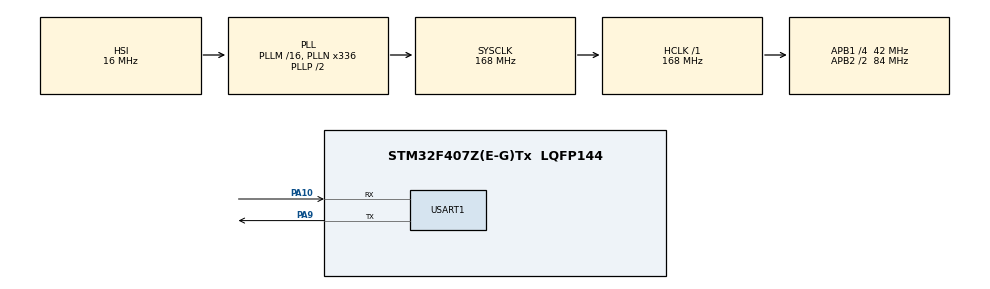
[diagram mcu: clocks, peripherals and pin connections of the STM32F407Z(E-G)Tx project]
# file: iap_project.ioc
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Mcu.Family=STM32F4
Mcu.Name=STM32F407Z(E-G)Tx
Mcu.Package=LQFP144
NVIC.PriorityGroup=NVIC_PRIORITYGROUP_4
NVIC.TIM6_DAC_IRQn=true\:0\:0\:false\:false\:true\:true\:true
NVIC.USART1_IRQn=true\:0\:0\:false\:false\:true\:true\:true
PA10.Mode=Asynchronous
PA10.Signal=USART1_RX
PA9.Mode=Asynchronous
PA9.Signal=USART1_TX
PC14-OSC32_IN.Mode=LSE-External-Oscillator
PC14-OSC32_IN.Signal=RCC_OSC32_IN
PC15-OSC32_OUT.Mode=LSE-External-Oscillator
PC15-OSC32_OUT.Signal=RCC_OSC32_OUT
PH0-OSC_IN.Mode=HSE-External-Oscillator
PH0-OSC_IN.Signal=RCC_OSC_IN
PH1-OSC_OUT.Mode=HSE-External-Oscillator
PH1-OSC_OUT.Signal=RCC_OSC_OUT
ProjectManager.HeapSize=0x200
ProjectManager.StackSize=0x400
ProjectManager.TargetToolchain=MDK-ARM V5
RCC.48MHZClocksFreq_Value=84000000
RCC.AHBFreq_Value=168000000
RCC.APB1CLKDivider=RCC_HCLK_DIV4
RCC.APB1Freq_Value=42000000
RCC.APB1TimFreq_Value=84000000
RCC.APB2CLKDivider=RCC_HCLK_DIV2
RCC.APB2Freq_Value=84000000
RCC.APB2TimFreq_Value=168000000
RCC.CortexFreq_Value=168000000
RCC.HCLKFreq_Value=168000000
RCC.HSE_VALUE=25000000
RCC.HSI_VALUE=16000000
RCC.PLLN=336
RCC.SYSCLKFreq_VALUE=168000000
RCC.SYSCLKSource=RCC_SYSCLKSOURCE_PLLCLK
RCC.VCOOutputFreq_Value=336000000
TIM6.AutoReloadPreload=TIM_AUTORELOAD_PRELOAD_ENABLE
TIM6.Period=999
TIM6.Prescaler=83
USART1.VirtualMode=VM_ASYNC
VP_TIM6_VS_ClockSourceINT.Mode=Enable_Timer
board=custom

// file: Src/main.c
/* USER CODE BEGIN Header */
/**
  ******************************************************************************
  * @file           : main.c
  * @brief          : Main program body
  ******************************************************************************
  * @attention
  *
  * <h2><center>&copy; Copyright (c) 2019 STMicroelectronics.
  * All rights reserved.</center></h2>
  *
  * This software component is licensed by ST under BSD 3-Clause license,
  * the "License"; You may not use this file except in compliance with the
  * License. You may obtain a copy of the License at:
  *                        opensource.org/licenses/BSD-3-Clause
  *
  ******************************************************************************
  */
/* USER CODE END Header */

#include "main.h"
#include "tim.h"
#include "usart.h"
#include "gpio.h"

/* USER CODE BEGIN Includes */
#include "stmflash.h"
#include "iap.h"
/* USER CODE END Includes */

void SystemClock_Config(void);

int main(void)
{

  /* MCU Configuration--------------------------------------------------------*/

  /* Reset of all peripherals, Initializes the Flash interface and the Systick. */
  HAL_Init();

  /* Configure the system clock */
  SystemClock_Config();

  /* Initialize all configured peripherals */
  MX_GPIO_Init();
  MX_USART1_UART_Init();
  MX_TIM6_Init();
  /* USER CODE BEGIN 2 */
	HAL_UART_Receive_IT(&huart1, (uint8_t*)&Res, 1);
	HAL_TIM_Base_Start_IT(&htim6);
	//STMFLASH_Write(ADDR_FLASH_SECTOR_9, &tmpText, 1);

  /* USER CODE END 2 */

  /* Infinite loop */
  /* USER CODE BEGIN WHILE */
  while (1)
  {
		HAL_Delay(100);
		if(rxFinishState == 1)
		{
			if(((*(volatile uint32_t*)(0X20001000+4))&0xFF000000)==0x08000000){//判断是否为0X08XXXXXX.
				IAP_Write_APPbin(FLASH_APP_ADDR, (uint8_t*)USART_RX_BUF, USART_RX_CNT);
				myPrintf("APP接收完成\r\n");
			}
			USART_RX_CNT = 0;
			rxFinishState = 0;
			if(((*(volatile uint32_t*)(0X20001000+4))&0xFF000000)==0x08000000){//判断是否为0X08XXXXXX.
				IAP_Load_APP(FLASH_APP_ADDR);
			}
		}
    /* USER CODE END WHILE */

  }
}

void SystemClock_Config(void)
{
  RCC_OscInitTypeDef RCC_OscInitStruct = {0};
  RCC_ClkInitTypeDef RCC_ClkInitStruct = {0};

  /** Configure the main internal regulator output voltage
  */
  __HAL_RCC_PWR_CLK_ENABLE();
  __HAL_PWR_VOLTAGESCALING_CONFIG(PWR_REGULATOR_VOLTAGE_SCALE1);
  /** Initializes the CPU, AHB and APB busses clocks
  */
  RCC_OscInitStruct.OscillatorType = RCC_OSCILLATORTYPE_HSI;
  RCC_OscInitStruct.HSIState = RCC_HSI_ON;
  RCC_OscInitStruct.HSICalibrationValue = RCC_HSICALIBRATION_DEFAULT;
  RCC_OscInitStruct.PLL.PLLState = RCC_PLL_ON;
  RCC_OscInitStruct.PLL.PLLSource = RCC_PLLSOURCE_HSI;
  RCC_OscInitStruct.PLL.PLLM = 16;
  RCC_OscInitStruct.PLL.PLLN = 336;
  RCC_OscInitStruct.PLL.PLLP = RCC_PLLP_DIV2;
  RCC_OscInitStruct.PLL.PLLQ = 4;
  if (HAL_RCC_OscConfig(&RCC_OscInitStruct) != HAL_OK)
  {
    Error_Handler();
  }
  /** Initializes the CPU, AHB and APB busses clocks
  */
  RCC_ClkInitStruct.ClockType = RCC_CLOCKTYPE_HCLK|RCC_CLOCKTYPE_SYSCLK
                              |RCC_CLOCKTYPE_PCLK1|RCC_CLOCKTYPE_PCLK2;
  RCC_ClkInitStruct.SYSCLKSource = RCC_SYSCLKSOURCE_PLLCLK;
  RCC_ClkInitStruct.AHBCLKDivider = RCC_SYSCLK_DIV1;
  RCC_ClkInitStruct.APB1CLKDivider = RCC_HCLK_DIV4;
  RCC_ClkInitStruct.APB2CLKDivider = RCC_HCLK_DIV2;

  if (HAL_RCC_ClockConfig(&RCC_ClkInitStruct, FLASH_LATENCY_5) != HAL_OK)
  {
    Error_Handler();
  }
}

void Error_Handler(void)
{
}

/************************ (C) COPYRIGHT STMicroelectronics *****END OF FILE****/
